# nrf54h20_enga_application register map
Vendor: Nordic Semiconductor; Series: nRF54h; File version: 1
CPU: CM33 r0p4, little endian, MPU, FPU, 3 interrupt priority bits, 480 interrupts, 4 SAU regions
Registers are 32-bit, read-write, reset 0x0 unless marked. A register's access mark holds for its fields unless they carry their own. Offsets are from the block's base; [hi:lo] are bit positions; lines under a group give offsets from that group; {n}, {i} and the like mark numbered series; 'fields as' and 'values as' point back to an identical list.

## GLOBAL_I3CCORE120_NS (part 1 of 2) — I3CCORE 0
Base 0x2FBE0000
Same registers: GLOBAL_I3CCORE121_NS 0x2FBE1000
0x00 CORE group — Unspecified
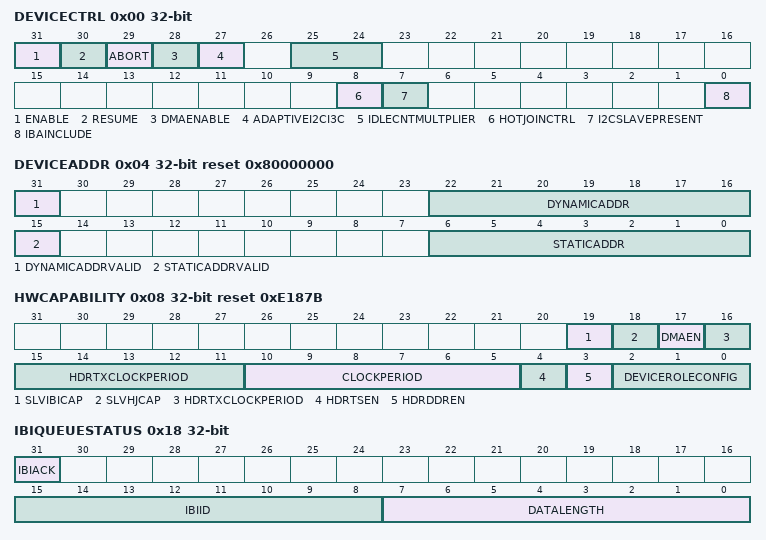
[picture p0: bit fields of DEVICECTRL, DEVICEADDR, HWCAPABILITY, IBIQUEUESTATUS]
  0x00 DEVICECTRL — DWC_mipi_i3c control Register
    [31] ENABLE — Controls whether or not DWC_mipi_i3c is enabled.
      0=DISABLE (Disables the DWC_mipi_i3c controller); 1=ENABLE (Enables the DWC_mipi_i3c controller.)
    [30] RESUME — DWC_mipi_i3c Resume
    [29] ABORT — DWC_mipi_i3c Abort
    [28] DMAENABLE — DMA Handshake Interface Enable
      0=DISABLE (The DMA handshake control has no significance.); 1=ENABLE (Enables the DMA handshake control to interact with external DMA.)
    [27] ADAPTIVEI2CI3C — This field is used in Slave mode of operation.
    [25:24] IDLECNTMULTPLIER — Idle Count Multiplier
      0=MultiplyBy1 (Unspecified); 1=MultiplyBy2 (Unspecified); 2=MultiplyBy4 (Unspecified); 3=MultiplyBy8 (Unspecified)
    [8] HOTJOINCTRL — Hot-Join ACK/NACK Control
      0=DISABLED (Unspecified); 1=ENABLED (Unspecified)
    [7] I2CSLAVEPRESENT
      0=DISABLED (Unspecified); 1=ENABLED (Unspecified)
    [0] IBAINCLUDE — I3C Broadcast Address include
      0=NOT_INCLUDED (Unspecified); 1=INCLUDED (Unspecified)
  0x04 DEVICEADDR reset 0x80000000 — In the master mode of operation this Register is used to program the Device Dynamic Addresses and its respective valid bit.
    [31] DYNAMICADDRVALID — Dynamic Address Valid
      0=INVALID (Unspecified); 1=VALID (Unspecified)
    [22:16] DYNAMICADDR — Device Dynamic Address.
    [15] STATICADDRVALID — Static Address Valid.
      0=INVALID (Unspecified); 1=VALID (Unspecified)
    [6:0] STATICADDR — Device Static Address.
  0x08 HWCAPABILITY reset 0xE187B — Hardware Capability register
    [19] SLVIBICAP ro — Reflects the IC_SLV_IBI Configurable Parameter.
    [18] SLVHJCAP ro — Reflects the IC_SLV_HJ Configurable Parameter.
    [17] DMAEN ro — Reflects the IC_HAS_DMA Configurable Parameter.
    [16:11] HDRTXCLOCKPERIOD ro — Reflects the IC_HDR_TX_CLK_PERIOD Configurable Parameter.
    [10:5] CLOCKPERIOD ro — Reflects the IC_CLK_PERIOD Configurable Parameter
    [4] HDRTSEN ro — Reflects the IC_SPEED_HDR_TS Configurable Parameter.
      0=NOTSUPPORTED (HDR-TS not supported); 1=SUPPORTED (HDR-TS supported)
    [3] HDRDDREN ro — Reflects the IC_SPEED_HDR_DDR Configurable Parameter.
      0=NOTSUPPORTED (HDR-DDR not supported); 1=SUPPORTED (HDR-DDR supported)
    [2:0] DEVICEROLECONFIG ro — Reflects the IC_DEVICE_ROLE Configurable Parameter.
      1=MASTER (Master Only); 2=PMASTERSLAVE (Programmable Master-Slave); 3=SECONDARYMASTER; 4=SLAVE (Slave Only)
  0x0C COMMANDQUEUEPORT
    [31:0] COMMAND wo — 32 bit command
  0x10 RESPONSEQUEUEPORT
    [31:0] RESPONSE ro — 32 bit Response
  0x14 RXDATAPORT — Receive Data Port Register
    [31:0] RXDATAPORT ro — Receive Data Port.
  0x14 TXDATAPORT (alternate view of RXDATAPORT) — Transmit Data Port Register
    [31:0] TXDATAPORT wo — Transmit Data Port
  0x18 IBIQUEUEDATA — In-Band Interrupt Queue Data Register
    [31:0] IBIDATA ro — In-Band Interrupt Data
  0x18 IBIQUEUESTATUS (alternate view of IBIQUEUEDATA) — In-Band Interrupt Queue Status Register
    [31] IBIACK ro — The acknowledge bit of the IBI Received Status (IBISTS) bitfield.
      0=ACK (Responded with ACK); 1=NACK (Responded with NACK)
    [15:8] IBIID ro — IBI Identifier.
    [7:0] DATALENGTH ro — In-Band Interrupt data length.
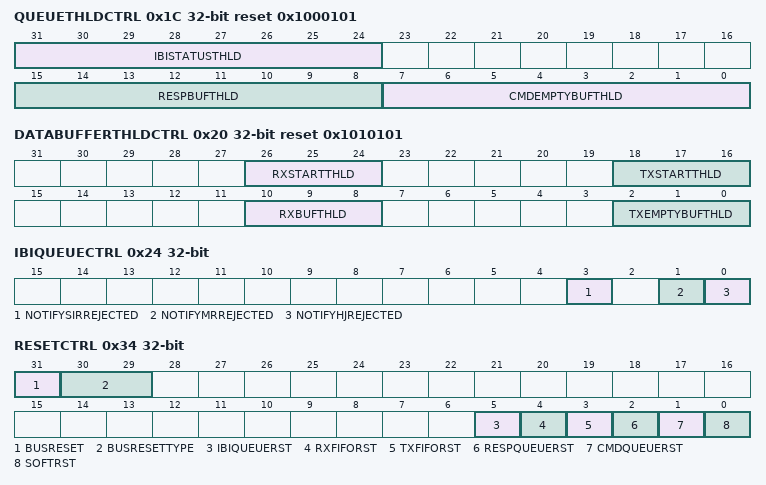
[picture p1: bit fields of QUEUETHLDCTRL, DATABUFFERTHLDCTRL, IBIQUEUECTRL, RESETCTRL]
  0x1C QUEUETHLDCTRL reset 0x1000101 — Queue Threshold Control Register
    [31:24] IBISTATUSTHLD — In-Band Interrupt Status Threshold Value.
    [15:8] RESPBUFTHLD — Response Buffer Threshold Value.
    [7:0] CMDEMPTYBUFTHLD — Command Buffer Empty Threshold Value.
  0x20 DATABUFFERTHLDCTRL reset 0x1010101 — Data Buffer Threshold Control Register
    [26:24] RXSTARTTHLD — Receive Start Threshold Value
      0=THRESHOLD1 (Unspecified); 1=THRESHOLD4 (Unspecified); 2=THRESHOLD8 (Unspecified); 3=THRESHOLD16 (Unspecified); 4=THRESHOLD32 (Unspecified); 5=THRESHOLD64 (Unspecified)
    [18:16] TXSTARTTHLD — Transfer Start Threshold Value
      values as RXSTARTTHLD
    [10:8] RXBUFTHLD — Receive Buffer Threshold Value
      values as RXSTARTTHLD
    [2:0] TXEMPTYBUFTHLD — Transmit Buffer Threshold Value
      0=THRESHOLD1 (Unspecified); 1=THRESHOLD14 (Unspecified); 2=THRESHOLD18 (Unspecified); 3=THRESHOLD116 (Unspecified); 4=THRESHOLD132 (Unspecified); 5=THRESHOLD164 (Unspecified)
  0x24 IBIQUEUECTRL — This Register is used to control whether or not to intimate the application if an IBI request is rejected (Nacked).
    [3] NOTIFYSIRREJECTED — Notify Rejected Slave Interrupt Request Control.
      0=DISABLED (Suppress passing the IBI Status to the IBI FIFO (hence not notifying the application) when a Slave Interrupt Request is NACKed and auto-disabled based on the IBI_SIR_REQ_REJECT Register.); 1=ENABLED (Writes IBI Status to the IBI FIFO (hence notifying the application) when a Slave Interrupt Request is NACKed and auto-disabled based on the IBI_SIR_REQ_REJECT Register.)
    [1] NOTIFYMRREJECTED — Notify Rejected Master Request Control.
      0=DISABLED (Suppress passing the IBI Status to the IBI FIFO (hence not notifying the application) when a MR Request is NACKed and auto-disabled based on the IBI_MR_REQ_REJECT Register.); 1=ENABLED (Writes IBI Status to the IBI FIFO (hence notifying the application) when a MR Request is NACKed and auto-disabled based on the IBI_MR_REQ_REJECT Register.)
    [0] NOTIFYHJREJECTED — Notify Rejected Hot-Join Control.
      0=DISABLED (Unspecified); 1=ENABLED (Unspecified)
  0x2C IBIMRREQREJECT — IBI Master Request Rejection Control Register.
    [31:0] MRREQREJECT — In-band Master Request Reject.
      0=ACK (ACK Master Request.); 1=NACK (NACK and send Directed DISEC CCC to disable the interrupting slave.)
  0x30 IBISIRREQREJECT — IBI SIR Request Rejection Control
    [31:0] SIRREQREJECT — In-band Slave Interrupt Request Reject
      0=ACK (ACK the SIR Request.); 1=NACK (NACK and send directed auto disable CCC.)
  0x34 RESETCTRL — This Register is used for general software reset and for individual buffer reset.
    [31] BUSRESET
    [30:29] BUSRESETTYPE
      0=EXIT (Exit Pattern.); 3=SCL_LOW_RESET (SCL_LOW_RESET Pattern.)
    [5] IBIQUEUERST — IBI Queue Software Reset.
    [4] RXFIFORST — Receive Buffer Software Reset.
    [3] TXFIFORST — Transmit Buffer Software Reset
    [2] RESPQUEUERST — Response Queue Software Reset
    [1] CMDQUEUERST — Command Queue Software Reset
    [0] SOFTRST — Core Software Reset.
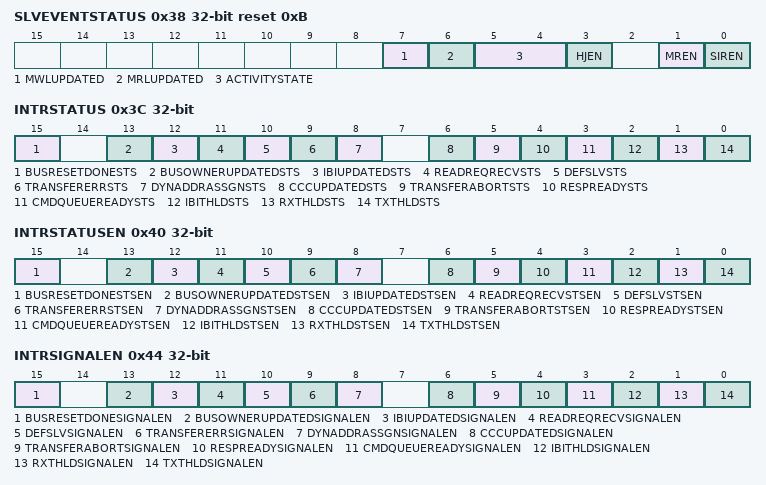
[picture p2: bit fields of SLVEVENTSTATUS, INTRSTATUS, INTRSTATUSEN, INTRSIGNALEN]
  0x38 SLVEVENTSTATUS reset 0xB — This register indicates the status/values of some events/controls that are relavant to slave mode of operation.
    [7] MWLUPDATED — MWL Updated Status.
    [6] MRLUPDATED — MRL Updated Status.
    [5:4] ACTIVITYSTATE ro — Activity State Status.
      {v}=ENTAS{v} (Unspecified) (v=0..3)
    [3] HJEN — Hot-Join Interrupt Enable
    [1] MREN ro — Master Request Enable.
    [0] SIREN ro — Slave Interrupt Request Enable.
  0x3C INTRSTATUS — Interrupt Status Register
    [15] BUSRESETDONESTS — Bus Reset Pattern Generation Done Status.
    [13] BUSOWNERUPDATEDSTS — This interrupt is set when the role of the controller changes from being a Master to Slave or vice versa.
    [12] IBIUPDATEDSTS — IBI status is updated.
    [11] READREQRECVSTS — Read Request Received.
    [10] DEFSLVSTS — Define Slave CCC Received Status.
    [9] TRANSFERERRSTS — Transfer Error Status.
    [8] DYNADDRASSGNSTS — Dynamic Address Assigned Status.
    [6] CCCUPDATEDSTS — CCC Table Updated Status.
    [5] TRANSFERABORTSTS — Transfer Abort Status.
    [4] RESPREADYSTS ro — Response Queue Ready Status.
    [3] CMDQUEUEREADYSTS ro — Command Queue Ready.
    [2] IBITHLDSTS ro — IBI Buffer Threshold Status.
    [1] RXTHLDSTS ro — Receive Buffer Threshold Status.
    [0] TXTHLDSTS ro — Transmit Buffer Threshold Status
  0x40 INTRSTATUSEN — Interrupt Status Enable Register.
    [15] BUSRESETDONESTSEN — Bus Reset Pattern Generation Done Status Enable.
    [13] BUSOWNERUPDATEDSTSEN — Bus owner Updated Status Enable
    [12] IBIUPDATEDSTSEN — IBI Updated Status Enable
    [11] READREQRECVSTSEN — Read Request Received Status Enable
    [10] DEFSLVSTSEN — Define Slave CCC Received Status Enable
    [9] TRANSFERERRSTSEN — Transfer Error Status Enable
    [8] DYNADDRASSGNSTSEN — Dynamic Address Assigned Status Enable
    [6] CCCUPDATEDSTSEN — CCC Table Updated Status Enable.
    [5] TRANSFERABORTSTSEN — Transfer Abort Status Enable.
    [4] RESPREADYSTSEN — Response Queue Ready Status Enable
    [3] CMDQUEUEREADYSTSEN — Command Queue Ready Status Enable
    [2] IBITHLDSTSEN — IBI Buffer Threshold Status Enable.
    [1] RXTHLDSTSEN — Receive Buffer Threshold Status Enable
    [0] TXTHLDSTSEN — Transmit Buffer Threshold Status Enable.
  0x44 INTRSIGNALEN — Interrupt Signal Enable Register
    [15] BUSRESETDONESIGNALEN — Bus Reset Pattern Generation Done Signal Enable.
    [13] BUSOWNERUPDATEDSIGNALEN — Bus owner Updated Signal Enable
    [12] IBIUPDATEDSIGNALEN — IBI Updated Signal Enable
    [11] READREQRECVSIGNALEN — Read Request Received Signal Enable
    [10] DEFSLVSIGNALEN — Define Slave CCC Received Signal Enable
    [9] TRANSFERERRSIGNALEN — Transfer Error Signal Enable
    [8] DYNADDRASSGNSIGNALEN — Dynamic Address Assigned Signal Enable
    [6] CCCUPDATEDSIGNALEN — CCC Table Updated Signal Enable
    [5] TRANSFERABORTSIGNALEN — Transfer Abort Signal Enable
    [4] RESPREADYSIGNALEN — Response Queue Ready Signal Enable
    [3] CMDQUEUEREADYSIGNALEN — Command Queue Ready Signal Enable
    [2] IBITHLDSIGNALEN — IBI Buffer Threshold Signal Enable
    [1] RXTHLDSIGNALEN — Receive Buffer Threshold Signal Enable
    [0] TXTHLDSIGNALEN — Transmit Buffer Threshold Signal Enable
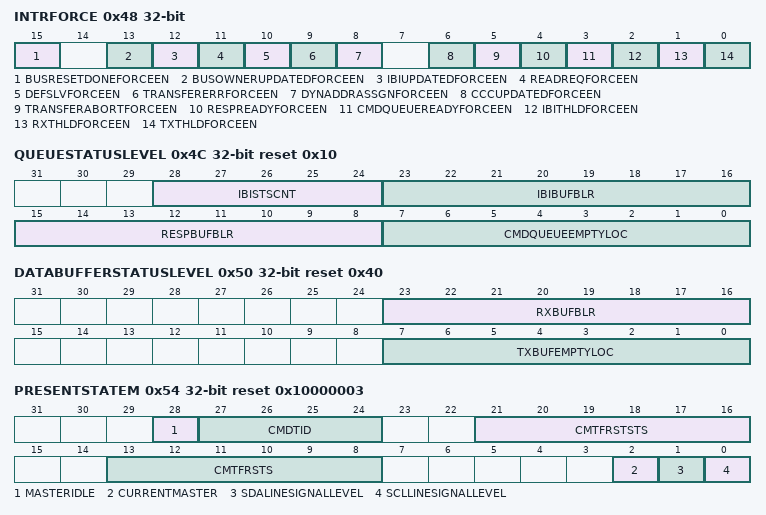
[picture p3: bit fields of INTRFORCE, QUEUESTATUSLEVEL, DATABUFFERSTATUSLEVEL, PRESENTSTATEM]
  0x48 INTRFORCE — Interrupt Force Enable Register
    [15] BUSRESETDONEFORCEEN wo — Bus Reset Pattern Generation Done Force Enable.
    [13] BUSOWNERUPDATEDFORCEEN wo — Bus owner Updated Force Enable
    [12] IBIUPDATEDFORCEEN wo — IBI Updated Force Enable
    [11] READREQFORCEEN wo — Read Request Received Force Enable
    [10] DEFSLVFORCEEN wo — Define Slave CCC Received Force Enable
    [9] TRANSFERERRFORCEEN wo — Transfer Error Force Enable
    [8] DYNADDRASSGNFORCEEN wo — Dynamic Address Assigned Force Enable
    [6] CCCUPDATEDFORCEEN wo — CCC Table Updated Force Enable
    [5] TRANSFERABORTFORCEEN wo — Transfer Abort Force Enable
    [4] RESPREADYFORCEEN wo — Response Queue Ready Force Enable
    [3] CMDQUEUEREADYFORCEEN wo — Command Queue Ready Force Enable
    [2] IBITHLDFORCEEN wo — IBI Buffer Threshold Force Enable
    [1] RXTHLDFORCEEN wo — Receive Buffer Threshold Force Enable
    [0] TXTHLDFORCEEN wo — Transmit Buffer Threshold Force Enable
  0x4C QUEUESTATUSLEVEL reset 0x10
    [28:24] IBISTSCNT ro — IBI Buffer Status Count.
    [23:16] IBIBUFBLR ro — IBI Buffer Level Value.
    [15:8] RESPBUFBLR ro — Response Buffer Level Value.
    [7:0] CMDQUEUEEMPTYLOC ro — Command Queue Empty Locations.
  0x50 DATABUFFERSTATUSLEVEL reset 0x40
    [23:16] RXBUFBLR ro — Receive Buffer Level Value.
    [7:0] TXBUFEMPTYLOC ro — Transmit Buffer Empty Level Value.
  0x54 PRESENTSTATEM reset 0x10000003 — The user can get status of the DWC_mipi_i3c Controller from this 32-bit read only register (Master).
    [28] MASTERIDLE ro — This field reflects whether the Master Controller is in Idle state or not.
      0=MST_NOT_IDLE (Unspecified); 1=MST_IDLE (Unspecified)
    [27:24] CMDTID ro — This field reflects the Transaction-ID of the current executing command.
    [21:16] CMTFRSTSTS ro — Current Master Transfer State Status.
      0=IDLE (Controller is Idle state, waiting for commands from application or Slave initated In-band Interrupt.); 1=START (START Generation State.); 2=RESTART (RESTART Generation State.); 3=STOP (STOP Genration State.); 4=STARTH (START Hold Generation for the Slave Initiated START State.); 5=BWADDRGEN (Broadcast Write Address Header(7h7E,W) Generation State.); 6=BRADDRGEN (Broadcast Read Address Header(7h7E,R) Generation State.); 7=DAA (Dynamic Address Assignment State.); 8=ADDRGEN (Slave Address Generation State.); 11=CCCBYTEGEN (CCC Byte Generation State.); 12=HDRCMDGEN (HDR Command Generation State.); 13=WTRANSFER (Write Data Transfer State.); 14=RTRANSFER (Read Data Transfer State.); 15=RIBI (In-Band Interrupt(SIR) Read Data State.); 16=IBIAUTODISABLE (In-Band Interrupt Auto-Disable State); 17=DDRCRCGEN (HDR-DDR CRC Data Generation/Receive State.); 18=CLKEXTEND (Clock Extension State.); 19=HALT (Halt State.)
    [13:8] CMTFRSTS ro — Transfer Type Status
      0=IDLE (Controller is in Idle state, waiting for commands from application or Slave initated In-band Interrupt.); 1=BCCCWTRANSFER (Broadcast CCC Write Transfer.); 2=DCCCWTRANSFER (Directed CCC Write Transfer.); 3=DCCCRTRANSFER (Directed CCC Read Transfer.); 4=ENTDAATRANSFER (ENTDAA Address Assignment Transfer.); 5=SETDASATRANSFER (SETDASA Address Assignment Transfer.); 6=SDRWTRANSFER (Private I3C SDR Write Transfer.); 7=SDRRTRANSFER (Private I3C SDR Read Transfer.); 8=SDRWTRANSFERI2C (Private I2C SDR Write Transfer.); 9=SDRRTRANSFERI2C (Private I2C SDR Read Transfer.); 10=TSWTRANSFER (Private HDR Ternary Symbol(TS) Write Transfer.); 11=TSRTRANSFER (Private HDR Ternary Symbol(TS) Read Transfer.); 12=DDRWTRANSFER (Private HDR Double-Data Rate(DDR) Write Transfer.); 13=DDRRTRANSFER (Private HDR Double-Data Rate(DDR) Read Transfer.); 14=IBITRANSFER (Servicing In-Band Interrupt Transfer.); 15=HALT (Halt state. Controller is in Halt State, waiting for the application to resume through DEVICE_CTRL Register.)
    [2] CURRENTMASTER ro — This Bit is used to check whether the Master is Current Master or not.
      0=NOT_BUS_OWNER (Master is not Current Master); 1=BUS_OWNER (Master is Current Master)
    [1] SDALINESIGNALLEVEL ro — This bit is used to check the SDA line level to recover from errors and for debugging.
    [0] SCLLINESIGNALLEVEL ro — This bit is used to check the SCL line level to recover from errors and for debugging.
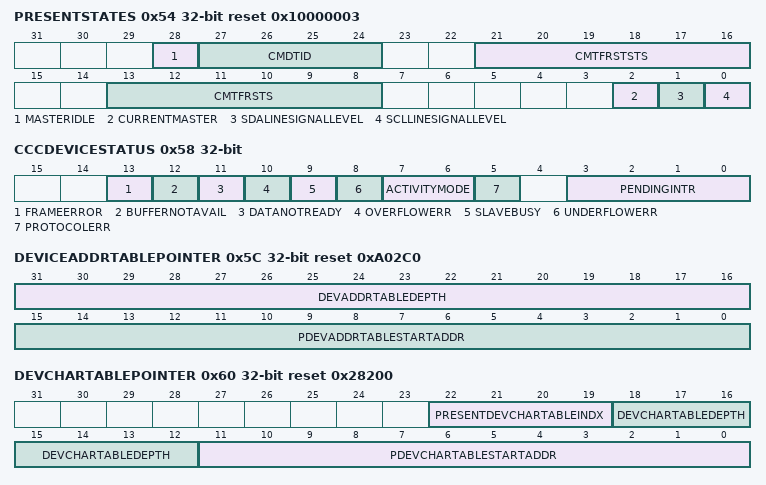
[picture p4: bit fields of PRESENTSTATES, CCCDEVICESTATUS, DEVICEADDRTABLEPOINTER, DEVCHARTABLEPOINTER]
  0x54 PRESENTSTATES reset 0x10000003 (alternate view of PRESENTSTATEM) — The user can get status of the DWC_mipi_i3c Controller from this 32-bit read only register (Slave).
    [28] MASTERIDLE ro — This field reflects whether the Master Controller is in Idle state or not.
      0=MST_NOT_IDLE (Unspecified); 1=MST_IDLE (Unspecified)
    [27:24] CMDTID ro — This field reflects the Transaction-ID of the current executing command.
    [21:16] CMTFRSTSTS ro — Current Master Transfer State Status.
    [13:8] CMTFRSTS ro — Transfer Type Status
      0=SLAVEIDLE (Controller is in Idle state.); 1=SLAVEHOTJOIN (Hot-Join transfer state.); 2=SLAVEIBITRANSFER (IBI transfer state.); 3=SLAVEWTRANSFER (Master write transfer ongoing.); 4=SLAVERPREFETCH (Read data prefetch state.); 5=SLAVERTRANSFER (Master read transfer ongoing.); 6=SLAVEHALT (Slave controller in Halt State waiting for resume from application.)
    [2] CURRENTMASTER ro — This Bit is used to check whether the Master is Current Master or not.
      values as CORE.PRESENTSTATEM.CURRENTMASTER
    [1] SDALINESIGNALLEVEL ro — This bit is used to check the SDA line level to recover from errors and for debugging.
    [0] SCLLINESIGNALLEVEL ro — This bit is used to check the SCL line level to recover from errors and for debugging.
  0x58 CCCDEVICESTATUS — Device Operating Status Register.
    [13] FRAMEERROR ro
    [12] BUFFERNOTAVAIL ro — Buffer not available
    [11] DATANOTREADY ro
    [10] OVERFLOWERR ro — Overflow Error
    [9] SLAVEBUSY ro
    [8] UNDERFLOWERR ro — Underflow error
    [7:6] ACTIVITYMODE ro
    [5] PROTOCOLERR ro — Protocol Error
    [3:0] PENDINGINTR ro — Pending Interrupt
  0x5C DEVICEADDRTABLEPOINTER reset 0xA02C0 — Pointer for Device Address Table
    [31:16] DEVADDRTABLEDEPTH ro — Depth of Device Address Table
    [15:0] PDEVADDRTABLESTARTADDR ro — Start Address of Device Address Table.
  0x60 DEVCHARTABLEPOINTER reset 0x28200 — Pointer for Device Characteristics Table
    [22:19] PRESENTDEVCHARTABLEINDX — Current index of Device Characteristics Table.
    [18:12] DEVCHARTABLEDEPTH ro — Depth of Device Characteristics Table
    [11:0] PDEVCHARTABLESTARTADDR ro — Start Address of Device Characteristics Table.
  0x6C VENDORSPECIFICREGPOINTER reset 0xB0 — Pointer for Vendor Specific Registers.
    [15:0] PVENDORREGSTARTADDR ro — Start Address of Vendor specific registers.
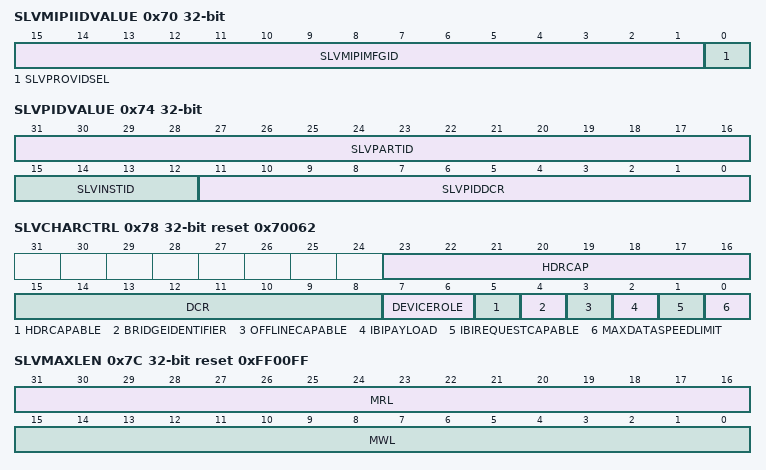
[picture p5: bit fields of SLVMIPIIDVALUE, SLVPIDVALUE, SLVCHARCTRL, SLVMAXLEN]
  0x70 SLVMIPIIDVALUE — I3C MIPI Manufacturer ID Register.
    [15:1] SLVMIPIMFGID — Specifies the MIPI Manufacturer ID.
    [0] SLVPROVIDSEL — Specifies the Provisional ID Type Selector (PID[32]).
  0x74 SLVPIDVALUE — I3C Normal Provisional ID Register.
    [31:16] SLVPARTID — Specifies the Part ID of DWC_mipi_i3c device (PID[31:16])
    [15:12] SLVINSTID — This field is used to program the instance ID of the Slave.
    [11:0] SLVPIDDCR — Specifies the additional 12-bit ID of DWC_mipi_i3c device (PID[11:0]).
  0x78 SLVCHARCTRL reset 0x70062 — I3C Slave Characteristic Register.
    [23:16] HDRCAP ro — I3C Device HDR Capability Register Value.
    [15:8] DCR — I3C Device Characteristic Value.
    [7:6] DEVICEROLE — Device Role field in Bus Characteristic Register (BCR[7:6]).
    [5] HDRCAPABLE — SDR Only or SDR and HDR Capable field in Bus Characteristic Register (BCR[5]).
    [4] BRIDGEIDENTIFIER ro — Bridge Identifier field in Bus Characteristic Register (BCR[4]).
    [3] OFFLINECAPABLE ro — Offline Capable field in Bus Characteristic Register (BCR[3]).
    [2] IBIPAYLOAD ro — IBI Payload field in Bus Characteristic Register (BCR[2]).
    [1] IBIREQUESTCAPABLE ro — IBI Request Capable field in Bus Characteristic Register (BCR[1]).
    [0] MAXDATASPEEDLIMIT — Max Data Speed Limitation field in Bus Characteristic Register (BCR[0]).
  0x7C SLVMAXLEN reset 0xFF00FF — I3C Max Write/Read Length Register.
    [31:16] MRL ro — I3C Device Max Read Length.
    [15:0] MWL ro — I3C Device Max Write Length
  0x80 MAXREADTURNAROUND — MXDS Maximum Read Turnaround Time.
    [23:0] MXDSMAXRDTURN ro — Specifies the maximum read turnaround time (in microseconds (us)) of DWC_mipi_i3c Slave.
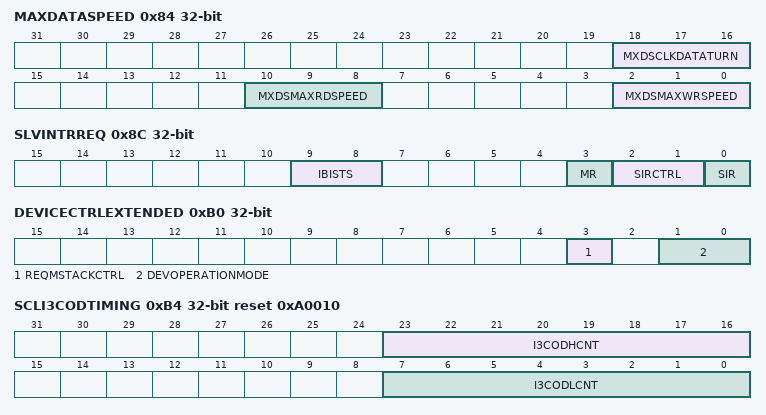
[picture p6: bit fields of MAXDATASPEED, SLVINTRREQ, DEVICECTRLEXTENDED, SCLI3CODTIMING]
  0x84 MAXDATASPEED — The values in this register are returned by the slave as GETACCMST CCC data.
    [18:16] MXDSCLKDATATURN — Specifies the clock to data turnaround time (Tsco parameter) of DWC_mipi_i3c Slave device
      {v}={v+8}NS (v=0..4)
    [10:8] MXDSMAXRDSPEED — Specifies the Maximum Sustained Data Rate for non-CCC messages sent by DWC_mipi_i3c Slave Device to Master Device
      0=12M5HZ (12.5MHz); 1=8MHZ; 2=6MHZ; 3=4MHZ; 4=2MHZ
    [2:0] MXDSMAXWRSPEED — Specifies the Maximum Sustained Data Rate for non-CCC messages sent by Master Device to DWC_mipi_i3c Slave device
      0=12M5HZ (12.5MHz); 1=8MHZ; 2=6MHZ; 3=4MHZ; 4=2MHZ
  0x8C SLVINTRREQ — This register is used in slave mode of operation.
    [9:8] IBISTS ro — IBI Completion Status
      1=ACCEPTED (IBI accepted by the Master (ACK response received)); 3=NOATTEMPT (IBI Not Attempted)
    [3] MR — Master Request
    [2:1] SIRCTRL — Slave Interrupt Request Control
      0=SEND (Send the Assigned Dynamic Address)
    [0] SIR — Slave Interrupt Request
  0x90 SLVTSXSYMBLTIMING reset 0x3F — TSP/TSL Symbol Timing Register
    [5:0] SLVTSXSYMBLCNT — TSP/TSL Symbol Count Value.
  0xB0 DEVICECTRLEXTENDED — Device Control Extended register.
    [3] REQMSTACKCTRL — In Slave mode of operation, this bit serves as a control to ACK/NACK GETACCMST CCC from current master.
      0=ACK (ACK GETACCMST CCC); 1=NACK (NACK GETACCMST CCC)
    [1:0] DEVOPERATIONMODE — This bit is used to select the Device Operation Mode before the controller is enabled.
      0=MASTER (Unspecified); 1=SLAVE (Unspecified)
  0xB4 SCLI3CODTIMING reset 0xA0010 — SCL I3C Open Drain Timing Register
    [23:16] I3CODHCNT — I3C Open Drain High Count.
    [7:0] I3CODLCNT — I3C Open Drain Low Count.
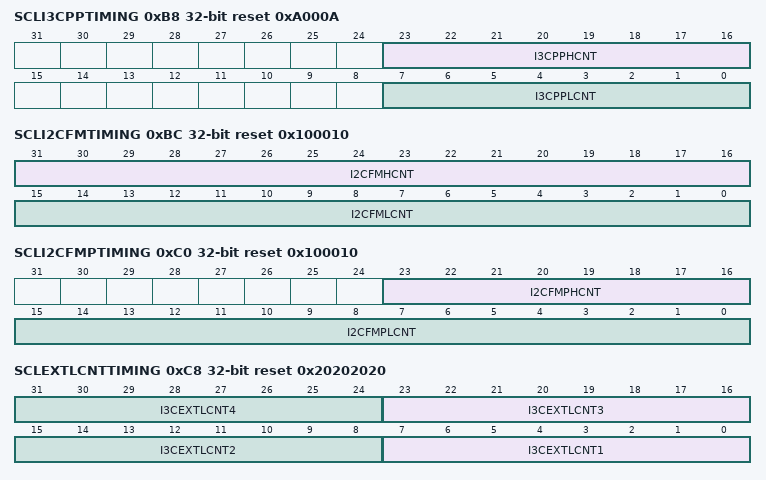
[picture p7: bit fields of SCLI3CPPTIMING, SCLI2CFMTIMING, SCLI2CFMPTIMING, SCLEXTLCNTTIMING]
  0xB8 SCLI3CPPTIMING reset 0xA000A — SCL I3C Push Pull Timing Register
    [23:16] I3CPPHCNT — I3C Push Pull High Count.
    [7:0] I3CPPLCNT — I3C Push Pull Low Count.
  0xBC SCLI2CFMTIMING reset 0x100010 — SCL I2C Fast Mode Timing Register
    [31:16] I2CFMHCNT — I2C Fast Mode High Count
    [15:0] I2CFMLCNT — I2C Fast Mode Low Count
  0xC0 SCLI2CFMPTIMING reset 0x100010 — SCL I2C Fast Mode Plus Timing Register
    [23:16] I2CFMPHCNT — I2C Fast Mode Plus High Count
    [15:0] I2CFMPLCNT — I2C Fast Mode Plus Low Count
  0xC8 SCLEXTLCNTTIMING reset 0x20202020 — SCL Extended Low Count Timing Register.
    [8n-1:8n-8] I3CEXTLCNT{n} (n=1..4) — I3C Extended Low Count Register {n}
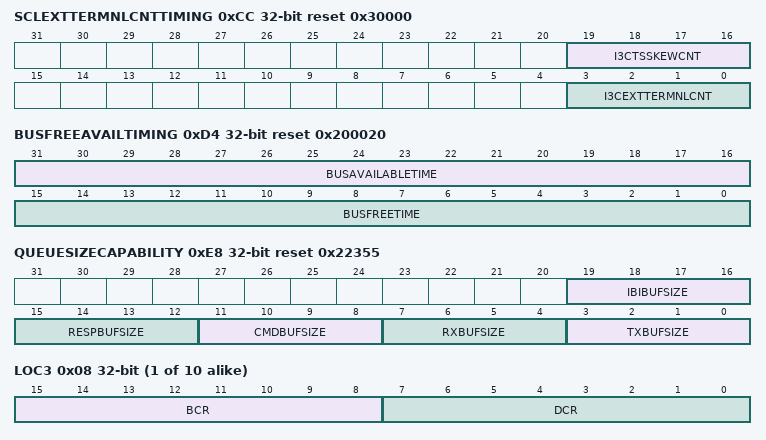
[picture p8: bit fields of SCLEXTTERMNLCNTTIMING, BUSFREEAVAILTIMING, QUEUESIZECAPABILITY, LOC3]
  0xCC SCLEXTTERMNLCNTTIMING reset 0x30000 — SCL Termination Bit Low Count Timing Register
    [19:16] I3CTSSKEWCNT — I3C HDR Ternary Skew Count.
    [3:0] I3CEXTTERMNLCNT — I3C Read Termination Bit Low count.
  0xD0 SDAHOLDSWITCHDLYTIMING reset 0x10000 — SDA Hold and Mode Switch Delay Timing Register
    [18:16] SDATXHOLD — This field controls the hold time (in term of the core clock period) of the transmit data (SDA) with
  0xD4 BUSFREEAVAILTIMING reset 0x200020 — Bus Free and Available Timing Register
    [31:16] BUSAVAILABLETIME — This register field is used only in Slave mode of operation
    [15:0] BUSFREETIME — This register field is used only in Master mode of operation
  0xD8 BUSIDLETIMING reset 0x20
    [19:0] BUSIDLETIME — Bus Idle Count Value.
  0xDC SCLLOWMSTEXTTIMEOUT reset 0x3567E0 — The SCL Low Master Extended Timeout register is used to define the duration of the SCL Low Bus Reset Pattern.
    [25:0] SCLLOWMSTTIMEOUTCOUNT — This count defines the number of core clock periods to count for generation of the SCL Low Bus Reset Pattern.
  0xE0 I3CVERID reset 0x3130302A — This register reflects the current release number of DWC_mipi_i3c
    [31:0] I3CVERID ro — Current release number
  0xE4 I3CVERTYPE reset 0x6C633033 — This register reflects the current release type of DWC_mipi_i3c.
    [31:0] I3CVERTYPE ro — Current release type
  0xE8 QUEUESIZECAPABILITY reset 0x22355 — This register reflects the configured size of the Data Buffer and Queues in DWC_mipi_i3c.
    [19:16] IBIBUFSIZE ro — IBI Queue Size
      0=2DWORD (2 DWORDS); 1=4DWORD (4 DWORDS); 2=8DWORD (8 DWORDS); 3=16DWORD (16 DWORDS)
    [15:12] RESPBUFSIZE ro — Response Queue Size
      values as IBIBUFSIZE
    [11:8] CMDBUFSIZE ro — Command Queue Size
      values as IBIBUFSIZE
    [7:4] RXBUFSIZE ro — Receive Data Buffer Size
      0=2DWORD (2 DWORDS); 1=4DWORD (4 DWORDS); 2=8DWORD (8 DWORDS); 3=16DWORD (16 DWORDS); 4=32DWORD (32 DWORDS); 5=64DWORD (64 DWORDS)
    [3:0] TXBUFSIZE ro — Transmit Data Buffer Size
      values as RXBUFSIZE
  {0x200+0x10*j} DEVCHARTABLE[{j}] (j=0..9) group — Unspecified
    0x00 LOC1 — Description cluster: Device Characteristic Table Location-1 of Device [n]
      [31:0] LSBPROVISIONALID ro — The LSB 32-bit value of Provisional-ID
    0x04 LOC2 — Description cluster: Device Characteristic Table Location-2 of Device [n]
      [15:0] MSBPROVISIONALID ro — The MSB 16-bit value of Provisional-ID
    0x08 LOC3 — Description cluster: Device Characteristic Table Location-3 of Device [n]
      [15:8] BCR ro — Bus Characteristic Value
      [7:0] DCR ro — Device Characteristic Value
    0x0C LOC4 — Description cluster: Device Characteristic Table Location-4 of Device [n]
      [7:0] DEVDYNAMICADDR ro — Device Dynamic Address assigned.
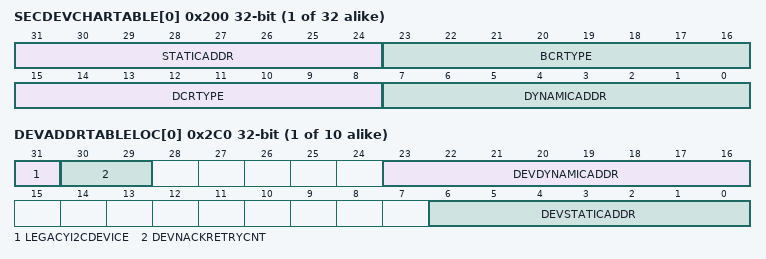
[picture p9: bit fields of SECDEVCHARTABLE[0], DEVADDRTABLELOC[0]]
  {0x200+4j} SECDEVCHARTABLE[{j}] (j=0..31) — Description collection: Secondary Master Device Characteristic Table Location of Device [n]
    [31:24] STATICADDR ro — The Static Addr of Device [n]
    [23:16] BCRTYPE ro — The BCR TYPE of Device [n]
    [15:8] DCRTYPE ro — The DCR TYPE of Device [n]
    [7:0] DYNAMICADDR ro — The Dynamic Addr of Device [n]
  {0x2C0+4j} DEVADDRTABLELOC[{j}] (j=0..9) — Description collection: Device Address Table of Device [n]
    [31] LEGACYI2CDEVICE — Legacy I2C device or not.
    [30:29] DEVNACKRETRYCNT — This field is used to set the Device NACK Retry count for the particular device.
    [23:16] DEVDYNAMICADDR — Device Dynamic Address with parity.
    [6:0] DEVSTATICADDR — Device Static Address.
